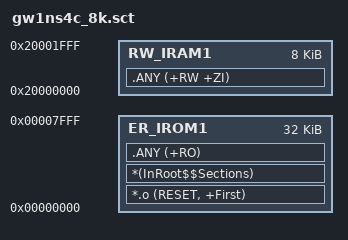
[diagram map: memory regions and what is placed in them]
; gw1ns4c_8k.sct — Gowin_EMPU GW1NS-4C: flash 32 KB ở 0x00000000, SRAM 8 KB ở 0x20000000 (IPUG931 bảng 2-1)
LR_IROM1 0x00000000 0x00008000 {
  ER_IROM1 0x00000000 0x00008000 {
    *.o (RESET, +First)
    *(InRoot$$Sections)
    .ANY (+RO)
  }
  RW_IRAM1 0x20000000 0x00002000 {
    .ANY (+RW +ZI)
  }
}
